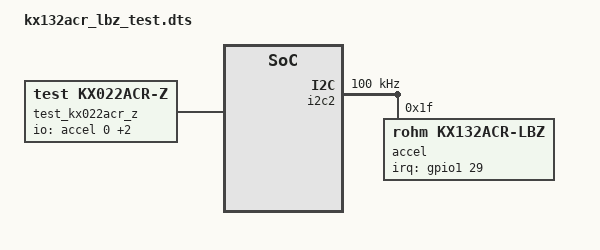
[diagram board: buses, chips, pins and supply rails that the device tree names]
/dts-v1/;
/plugin/;

/{ /* this is our device tree overlay root node */

	compatible = "ti,beaglebone", "ti,beaglebone-black";
	part-number = "BBB-I2C1"; // you can choose any name here but it should be memorable
 	version = "00A0";

	fragment@0 {
		target = <&am33xx_pinmux>; 

		__overlay__ {
//			i2c2_pins: pinmux_i2c2_pins {
//				pinctrl-single,pins = <
				/* 0x158 - pin 17.
				   0x15C - pin 18
					0x72:
					b[2:0] = 2 => mux mode 2 (i2c1 p17/p18,SCL/SDA)
					b[3] = 0 => pullup/pulldown enabled
					b[4] = 1 => pull-up, not pull down
					b[5] = 1 => receiver active
					b[6] = 1 => slew control slow
				*/
//				0x17C 0x73 /* P9_19 (I2C-2 SCL) (input, pull-u, mode 3) */
//				0x178 0x73 /* P9_20 (I2C-2 SDA) (input, pull-u, mode 3)*/
          			/* 0x158 0x72   spi0_d1.i2c1_sda */ 
          			/* 0x15C 0x72  spi0_cs0.i2c1_sdl */
/*				0xA4 0x7    */ /* pin 46, GPIO 2_7 mode 7 */
/*				0xA0 0x7    */ /* pin 45, GPIO 2_6 mode 7 */
/*				0x0c 0x7    */ /* pin 3, GPIO 1_6 mode 7 */
/*				0x10 0x7    */ /* pin 4, GPIO 1_7 mode 7 */
//        			>;
		};
	};
	fragment@1 {
		target = <&i2c2>;

		__overlay__ {
//			pinctrl-0 = <&i2c2_pins>;
			clock-frequency = <100000>;
			status = "okay";

			accel: accel@1f { /* the "test" defined as child of the i2c1 bus */
				compatible = "rohm,kx132acr-lbz";
				reg = <0x1f>;
				/* GPIO 1_29 - (connector 8, pin 26) for irq */
				interrupt-parent = <&gpio1>;
/*				interrupts = <29 GPIO_ACTIVE_LOW>; */
				interrupts = <29 8>;
				interrupt-names = "INT1";
				#io-channel-cells = <1>;
			};
		};
	};
	fragment@2 {
		target-path = "/";
		__overlay__ {
			test_kx022acr_z {
				compatible = "test,kx022acr-z";
				/*io-channels = <&accel 0>, <&accel 1>, <&accel 2>, <&accel 3>; */
				/*io-channel-names = "x", "y", "z", "timestamp"; */
				io-channels = <&accel 0>, <&accel 1>, <&accel 2>;
				io-channel-names = "x", "y", "z";

			};

		};
	};
}; /* root node end */
